VERSION "BMS_SIM DBC"

NS_ :

BS_:

BU_:
 BMS

BO_ 1568 BMS_Company_Info: 8 BMS
 SG_ CompanyName : 0|64@1+ (1,0) [0|0] "" BMS

BO_ 1569 VIN_car_info: 8 BMS
 SG_ Carname : 0|64@1+ (1,0) [0|0] "" BMS

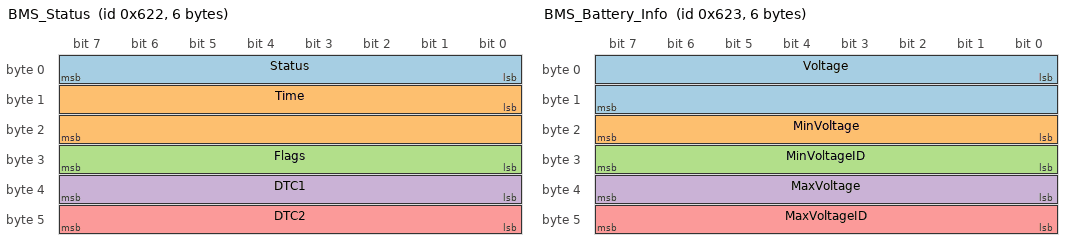
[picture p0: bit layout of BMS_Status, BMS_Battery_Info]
BO_ 1570 BMS_Status: 6 BMS
 SG_ Status : 0|8@1+ (1,0) [0|0] "" BMS
 SG_ Time : 8|16@1+ (1,0) [0|60] "s" BMS
 SG_ Flags : 24|8@1+ (1,0) [0|128] "" BMS
 SG_ DTC1 : 32|8@1+ (1,0) [0|128] "" BMS
 SG_ DTC2 : 40|8@1+ (1,0) [0|128] "" BMS

BO_ 1571 BMS_Battery_Info: 6 BMS
 SG_ Voltage : 0|16@1+ (1,0) [0|65536] "V" BMS
 SG_ MinVoltage : 16|8@1+ (0.1,0) [0|25.4] "V" BMS
 SG_ MinVoltageID : 24|8@1+ (1,0) [0|254] "" BMS
 SG_ MaxVoltage : 32|8@1+ (0.1,0) [0|25.4] "V" BMS
 SG_ MaxVoltageID : 40|8@1+ (1,0) [0|254] "" BMS

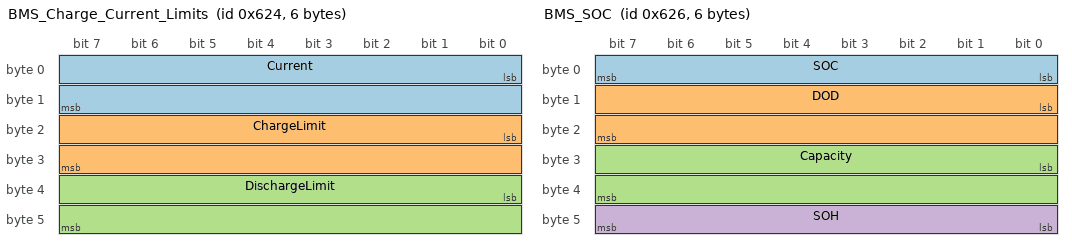
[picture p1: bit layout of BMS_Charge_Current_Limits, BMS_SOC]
BO_ 1572 BMS_Charge_Current_Limits: 6 BMS
 SG_ Current : 0|16@1- (1,0) [-32000|32000] "A" BMS
 SG_ ChargeLimit : 16|16@1+ (1,0) [0|32000]  "A" BMS
 SG_ DischargeLimit : 32|16@1+ (1,0) [0|32000] "A" BMS

BO_ 1574 BMS_SOC: 6 BMS
 SG_ SOC :  0|8@1+ (1,0) [0|100] "%" BMS
 SG_ DOD : 8|16@1+ (1,0) [0|65536] "Ah" BMS
 SG_ Capacity : 24|16@1+ (1,0) [0|65536] "Ah" BMS
 SG_ SOH : 40|8@1+ (1,0) [0|100] "%" BMS

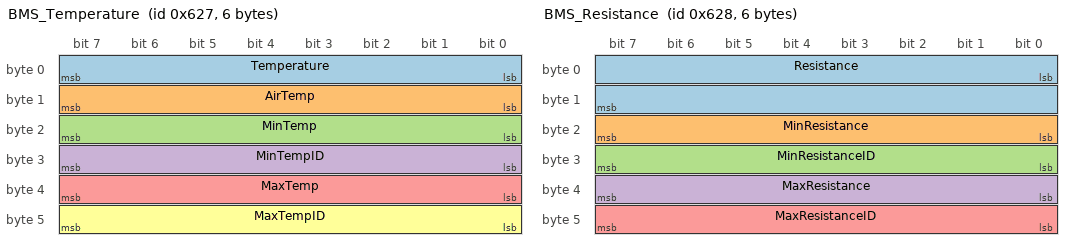
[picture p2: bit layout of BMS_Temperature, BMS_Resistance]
BO_ 1575 BMS_Temperature: 6 BMS
 SG_ Temperature : 0|8@1- (1,0) [-127|127] "°C" BMS
 SG_ AirTemp : 8|8@1- (1,0) [-127|127] "°C" BMS
 SG_ MinTemp : 16|8@1- (1,0) [-127|127] "°C" BMS
 SG_ MinTempID : 24|8@1+ (1,0) [0|254] "" BMS
 SG_ MaxTemp : 32|8@1- (1,0) [-127|127] "°C" BMS
 SG_ MaxTempID : 40|8@1+ (1,0) [0|254] "" BMS

BO_ 1576 BMS_Resistance: 6 BMS
 SG_ Resistance : 0|16@1+ (1,0) [0|65536] "Ω" BMS
 SG_ MinResistance : 16|8@1+ (0.1,0) [0|254]"mΩ" BMS
 SG_ MinResistanceID : 24|8@1+ (1,0) [0|254] "" BMS
 SG_ MaxResistance : 32|8@1+ (0.1,0) [0|254] "mΩ" BMS
 SG_ MaxResistanceID : 40|8@1+ (1,0) [0|254] "" BMS

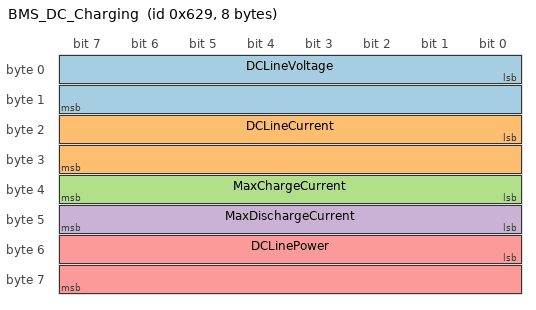
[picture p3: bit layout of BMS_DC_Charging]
BO_ 1577 BMS_DC_Charging: 8 BMS
 SG_ DCLineVoltage : 0|16@1+ (1,0) [0|65536] "V" BMS
 SG_ DCLineCurrent : 16|16@1+ (1,0) [0|127] "A" BMS
 SG_ MaxChargeCurrent : 32|8@1+ (1,0) [0|255] "A" BMS
 SG_ MaxDischargeCurrent : 40|8@1+ (1,0) [0|255] "A" BMS
 SG_ DCLinePower : 48|16@1+ (1,0) [0|32768] "W" BMS
